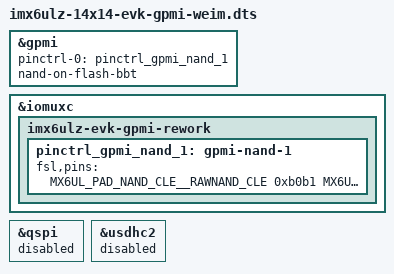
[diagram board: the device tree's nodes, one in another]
/*
 * Copyright 2018 NXP
 *
 * This program is free software; you can redistribute it and/or
 * modify it under the terms of the GNU General Public License
 * as published by the Free Software Foundation; either version 2
 * of the License, or (at your option) any later version.
 *
 * This program is distributed in the hope that it will be useful,
 * but WITHOUT ANY WARRANTY; without even the implied warranty of
 * MERCHANTABILITY or FITNESS FOR A PARTICULAR PURPOSE.  See the
 * GNU General Public License for more details.
 */

#include "imx6ulz-14x14-evk.dts"

&gpmi {
	pinctrl-names = "default";
	pinctrl-0 = <&pinctrl_gpmi_nand_1>;
	status = "okay";
	nand-on-flash-bbt;
};

&iomuxc {
	imx6ulz-evk-gpmi-rework {
		pinctrl_gpmi_nand_1: gpmi-nand-1 {
			fsl,pins = <
				MX6UL_PAD_NAND_CLE__RAWNAND_CLE         0xb0b1
				MX6UL_PAD_NAND_ALE__RAWNAND_ALE         0xb0b1
				MX6UL_PAD_NAND_WP_B__RAWNAND_WP_B       0xb0b1
				MX6UL_PAD_NAND_READY_B__RAWNAND_READY_B 0xb000
				MX6UL_PAD_NAND_CE0_B__RAWNAND_CE0_B     0xb0b1
				MX6UL_PAD_NAND_CE1_B__RAWNAND_CE1_B     0xb0b1
				MX6UL_PAD_NAND_RE_B__RAWNAND_RE_B       0xb0b1
				MX6UL_PAD_NAND_WE_B__RAWNAND_WE_B       0xb0b1
				MX6UL_PAD_NAND_DATA00__RAWNAND_DATA00   0xb0b1
				MX6UL_PAD_NAND_DATA01__RAWNAND_DATA01   0xb0b1
				MX6UL_PAD_NAND_DATA02__RAWNAND_DATA02   0xb0b1
				MX6UL_PAD_NAND_DATA03__RAWNAND_DATA03   0xb0b1
				MX6UL_PAD_NAND_DATA04__RAWNAND_DATA04   0xb0b1
				MX6UL_PAD_NAND_DATA05__RAWNAND_DATA05   0xb0b1
				MX6UL_PAD_NAND_DATA06__RAWNAND_DATA06   0xb0b1
				MX6UL_PAD_NAND_DATA07__RAWNAND_DATA07   0xb0b1
			>;
		};
	};
};

&qspi {
	status = "disabled";
};

&usdhc2 {
	status = "disabled";
};
